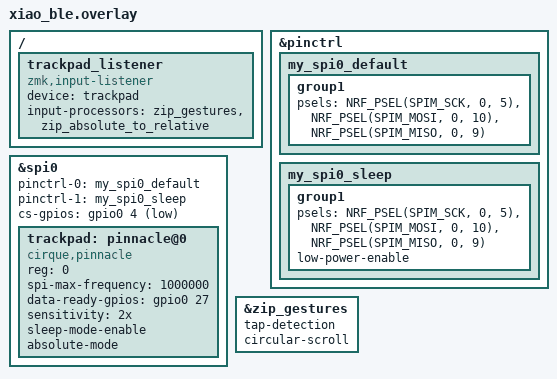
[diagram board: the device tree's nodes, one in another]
#include <dt-bindings/zmk/input_transform.h>
#include <dt-bindings/gpio/gpio.h>

/* Import gesture and coordinate translation input processors */
#include <behaviors/input_processor_gestures.dtsi>
#include <behaviors/input_processor_absolute_to_relative.dtsi>

&pinctrl {
    my_spi0_default: my_spi0_default {
        group1 {
            psels = <NRF_PSEL(SPIM_SCK, 0, 5)>,   // SCK Line -> Seeed Studio Pin D5
                    <NRF_PSEL(SPIM_MOSI, 0, 10)>, // MOSI Line -> Seeed Studio Pin D10
                    <NRF_PSEL(SPIM_MISO, 0, 9)>;  // MISO Line -> Seeed Studio Pin D9
        };
    };

    my_spi0_sleep: my_spi0_sleep {
        group1 {
            psels = <NRF_PSEL(SPIM_SCK, 0, 5)>,
                    <NRF_PSEL(SPIM_MOSI, 0, 10)>,
                    <NRF_PSEL(SPIM_MISO, 0, 9)>;
            low-power-enable;
        };
    };
};

&spi0 {
    status = "okay";
    pinctrl-0 = <&my_spi0_default>;
    pinctrl-1 = <&my_spi0_sleep>;
    pinctrl-names = "default", "sleep";
    cs-gpios = <&gpio0 4 GPIO_ACTIVE_LOW>; // CS line linked to Seeed Studio D2

    trackpad: pinnacle@0 {
        compatible = "cirque,pinnacle";
        reg = <0>;
        spi-max-frequency = <1000000>;
        status = "okay";
        data-ready-gpios = <&gpio0 27 GPIO_ACTIVE_HIGH>; // DR line linked to Seeed Studio D3
        sensitivity = "2x";
        sleep-mode-enable;
        
        /* Activate absolute mode for halfdane gestures */
        absolute-mode;
    };
};

/* Configure active gesture behavior settings */
&zip_gestures {
    tap-detection;
    circular-scroll;
};

/ {
    /* Route hardware trackpad input through the gesture pipeline */
    trackpad_listener {
        compatible = "zmk,input-listener";
        device = <&trackpad>;
        input-processors = <
            &zip_gestures
            &zip_absolute_to_relative
        >;
    };
};
